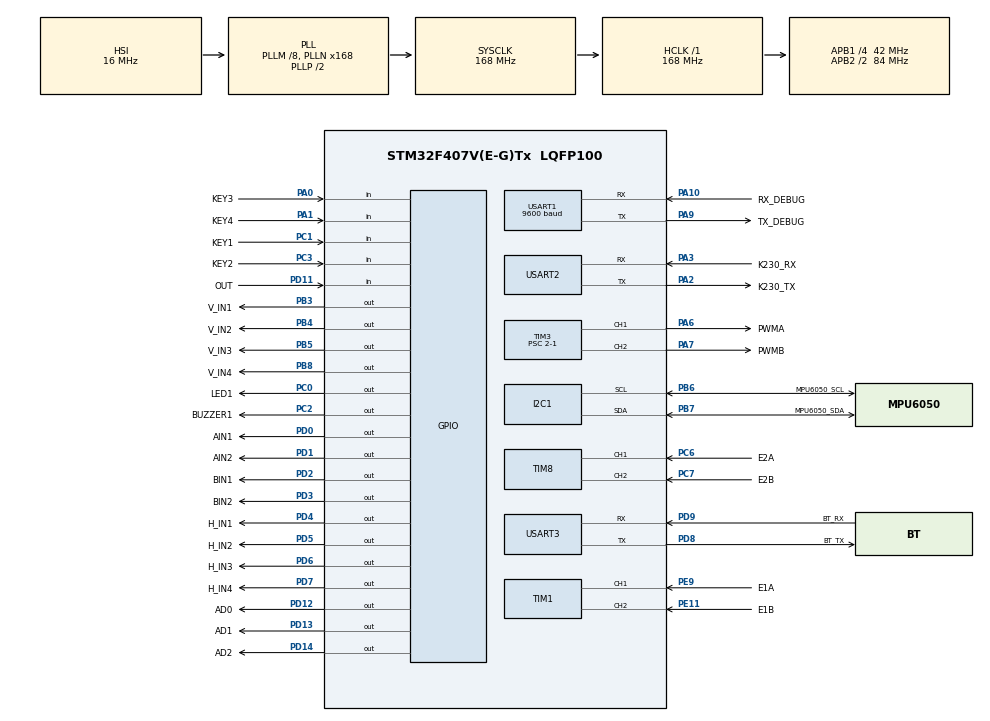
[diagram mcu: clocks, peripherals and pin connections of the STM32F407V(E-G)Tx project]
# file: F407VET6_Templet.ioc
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Dma.I2C1_RX.6.Direction=DMA_PERIPH_TO_MEMORY
Dma.I2C1_RX.6.FIFOMode=DMA_FIFOMODE_DISABLE
Dma.I2C1_RX.6.Instance=DMA1_Stream0
Dma.I2C1_RX.6.MemDataAlignment=DMA_MDATAALIGN_BYTE
Dma.I2C1_RX.6.MemInc=DMA_MINC_ENABLE
Dma.I2C1_RX.6.Mode=DMA_NORMAL
Dma.I2C1_RX.6.PeriphDataAlignment=DMA_PDATAALIGN_BYTE
Dma.I2C1_RX.6.PeriphInc=DMA_PINC_DISABLE
Dma.I2C1_RX.6.Priority=DMA_PRIORITY_LOW
Dma.I2C1_TX.7.Direction=DMA_MEMORY_TO_PERIPH
Dma.I2C1_TX.7.FIFOMode=DMA_FIFOMODE_DISABLE
Dma.I2C1_TX.7.Instance=DMA1_Stream7
Dma.I2C1_TX.7.MemDataAlignment=DMA_MDATAALIGN_BYTE
Dma.I2C1_TX.7.MemInc=DMA_MINC_ENABLE
Dma.I2C1_TX.7.Mode=DMA_NORMAL
Dma.I2C1_TX.7.PeriphDataAlignment=DMA_PDATAALIGN_BYTE
Dma.I2C1_TX.7.PeriphInc=DMA_PINC_DISABLE
Dma.I2C1_TX.7.Priority=DMA_PRIORITY_LOW
Dma.Request0=USART1_RX
Dma.Request1=USART1_TX
Dma.Request2=USART2_RX
Dma.Request3=USART2_TX
Dma.Request4=USART3_RX
Dma.Request5=USART3_TX
Dma.Request6=I2C1_RX
Dma.Request7=I2C1_TX
Dma.USART1_RX.0.Direction=DMA_PERIPH_TO_MEMORY
Dma.USART1_RX.0.FIFOMode=DMA_FIFOMODE_DISABLE
Dma.USART1_RX.0.Instance=DMA2_Stream2
Dma.USART1_RX.0.MemDataAlignment=DMA_MDATAALIGN_BYTE
Dma.USART1_RX.0.MemInc=DMA_MINC_ENABLE
Dma.USART1_RX.0.Mode=DMA_NORMAL
Dma.USART1_RX.0.PeriphDataAlignment=DMA_PDATAALIGN_BYTE
Dma.USART1_RX.0.PeriphInc=DMA_PINC_DISABLE
Dma.USART1_RX.0.Priority=DMA_PRIORITY_LOW
Dma.USART1_TX.1.Direction=DMA_MEMORY_TO_PERIPH
Dma.USART1_TX.1.FIFOMode=DMA_FIFOMODE_DISABLE
Dma.USART1_TX.1.Instance=DMA2_Stream7
Dma.USART1_TX.1.MemDataAlignment=DMA_MDATAALIGN_BYTE
Dma.USART1_TX.1.MemInc=DMA_MINC_ENABLE
Dma.USART1_TX.1.Mode=DMA_NORMAL
Dma.USART1_TX.1.PeriphDataAlignment=DMA_PDATAALIGN_BYTE
Dma.USART1_TX.1.PeriphInc=DMA_PINC_DISABLE
Dma.USART1_TX.1.Priority=DMA_PRIORITY_LOW
Dma.USART2_RX.2.Direction=DMA_PERIPH_TO_MEMORY
Dma.USART2_RX.2.FIFOMode=DMA_FIFOMODE_DISABLE
Dma.USART2_RX.2.Instance=DMA1_Stream5
Dma.USART2_RX.2.MemDataAlignment=DMA_MDATAALIGN_BYTE
Dma.USART2_RX.2.MemInc=DMA_MINC_ENABLE
Dma.USART2_RX.2.Mode=DMA_NORMAL
Dma.USART2_RX.2.PeriphDataAlignment=DMA_PDATAALIGN_BYTE
Dma.USART2_RX.2.PeriphInc=DMA_PINC_DISABLE
Dma.USART2_RX.2.Priority=DMA_PRIORITY_LOW
Dma.USART2_TX.3.Direction=DMA_MEMORY_TO_PERIPH
Dma.USART2_TX.3.FIFOMode=DMA_FIFOMODE_DISABLE
Dma.USART2_TX.3.Instance=DMA1_Stream6
Dma.USART2_TX.3.MemDataAlignment=DMA_MDATAALIGN_BYTE
Dma.USART2_TX.3.MemInc=DMA_MINC_ENABLE
Dma.USART2_TX.3.Mode=DMA_NORMAL
Dma.USART2_TX.3.PeriphDataAlignment=DMA_PDATAALIGN_BYTE
Dma.USART2_TX.3.PeriphInc=DMA_PINC_DISABLE
Dma.USART2_TX.3.Priority=DMA_PRIORITY_LOW
Dma.USART3_RX.4.Direction=DMA_PERIPH_TO_MEMORY
Dma.USART3_RX.4.FIFOMode=DMA_FIFOMODE_DISABLE
Dma.USART3_RX.4.Instance=DMA1_Stream1
Dma.USART3_RX.4.MemDataAlignment=DMA_MDATAALIGN_BYTE
Dma.USART3_RX.4.MemInc=DMA_MINC_ENABLE
Dma.USART3_RX.4.Mode=DMA_NORMAL
Dma.USART3_RX.4.PeriphDataAlignment=DMA_PDATAALIGN_BYTE
Dma.USART3_RX.4.PeriphInc=DMA_PINC_DISABLE
Dma.USART3_RX.4.Priority=DMA_PRIORITY_LOW
Dma.USART3_TX.5.Direction=DMA_MEMORY_TO_PERIPH
Dma.USART3_TX.5.FIFOMode=DMA_FIFOMODE_DISABLE
Dma.USART3_TX.5.Instance=DMA1_Stream3
Dma.USART3_TX.5.MemDataAlignment=DMA_MDATAALIGN_BYTE
Dma.USART3_TX.5.MemInc=DMA_MINC_ENABLE
Dma.USART3_TX.5.Mode=DMA_NORMAL
Dma.USART3_TX.5.PeriphDataAlignment=DMA_PDATAALIGN_BYTE
Dma.USART3_TX.5.PeriphInc=DMA_PINC_DISABLE
Dma.USART3_TX.5.Priority=DMA_PRIORITY_LOW
Mcu.Family=STM32F4
Mcu.Name=STM32F407V(E-G)Tx
Mcu.Package=LQFP100
NVIC.DMA1_Stream0_IRQn=true\:0\:0\:false\:false\:true\:false\:true\:true
NVIC.DMA1_Stream1_IRQn=true\:0\:0\:false\:false\:true\:false\:true\:true
NVIC.DMA1_Stream3_IRQn=true\:0\:0\:false\:false\:true\:false\:true\:true
NVIC.DMA1_Stream5_IRQn=true\:0\:0\:false\:false\:true\:false\:true\:true
NVIC.DMA1_Stream6_IRQn=true\:0\:0\:false\:false\:true\:false\:true\:true
NVIC.DMA1_Stream7_IRQn=true\:0\:0\:false\:false\:true\:false\:true\:true
NVIC.DMA2_Stream2_IRQn=true\:0\:0\:false\:false\:true\:false\:true\:true
NVIC.DMA2_Stream7_IRQn=true\:0\:0\:false\:false\:true\:false\:true\:true
NVIC.PriorityGroup=NVIC_PRIORITYGROUP_4
NVIC.TIM2_IRQn=true\:0\:0\:false\:false\:true\:true\:true\:true
NVIC.USART1_IRQn=true\:0\:0\:false\:false\:true\:true\:true\:true
NVIC.USART2_IRQn=true\:0\:0\:false\:false\:true\:true\:true\:true
NVIC.USART3_IRQn=true\:0\:0\:false\:false\:true\:true\:true\:true
PA0-WKUP.GPIO_Label=KEY3
PA0-WKUP.GPIO_PuPd=GPIO_PULLUP
PA0-WKUP.Signal=GPIO_Input
PA1.GPIO_Label=KEY4
PA1.GPIO_PuPd=GPIO_PULLUP
PA1.Signal=GPIO_Input
PA10.GPIO_Label=RX_DEBUG
PA10.Mode=Asynchronous
PA10.Signal=USART1_RX
PA13.Mode=Serial_Wire
PA13.Signal=SYS_JTMS-SWDIO
PA14.Mode=Serial_Wire
PA14.Signal=SYS_JTCK-SWCLK
PA2.GPIO_Label=K230_TX
PA2.Mode=Asynchronous
PA2.Signal=USART2_TX
PA3.GPIO_Label=K230_RX
PA3.Mode=Asynchronous
PA3.Signal=USART2_RX
PA6.GPIO_Label=PWMA
PA6.Signal=S_TIM3_CH1
PA7.GPIO_Label=PWMB
PA7.Signal=S_TIM3_CH2
PA9.GPIO_Label=TX_DEBUG
PA9.Mode=Asynchronous
PA9.Signal=USART1_TX
PB3.GPIO_Label=V_IN1
PB3.Signal=GPIO_Output
PB4.GPIO_Label=V_IN2
PB4.Signal=GPIO_Output
PB5.GPIO_Label=V_IN3
PB5.Signal=GPIO_Output
PB6.GPIO_Label=MPU6050_SCL
PB6.Mode=I2C
PB6.Signal=I2C1_SCL
PB7.GPIO_Label=MPU6050_SDA
PB7.Mode=I2C
PB7.Signal=I2C1_SDA
PB8.GPIO_Label=V_IN4
PB8.Signal=GPIO_Output
PC0.GPIO_Label=LED1
PC0.GPIO_Speed=GPIO_SPEED_FREQ_MEDIUM
PC0.Signal=GPIO_Output
PC1.GPIO_Label=KEY1
PC1.GPIO_PuPd=GPIO_PULLUP
PC1.Signal=GPIO_Input
PC2.GPIO_Label=BUZZER1
PC2.GPIO_Speed=GPIO_SPEED_FREQ_MEDIUM
PC2.Signal=GPIO_Output
PC3.GPIO_Label=KEY2
PC3.GPIO_PuPd=GPIO_PULLUP
PC3.Signal=GPIO_Input
PC6.GPIO_Label=E2A
PC6.Signal=S_TIM8_CH1
PC7.GPIO_Label=E2B
PC7.Signal=S_TIM8_CH2
PD0.GPIO_Label=AIN1
PD0.Signal=GPIO_Output
PD1.GPIO_Label=AIN2
PD1.Signal=GPIO_Output
PD11.GPIO_Label=OUT
PD11.Signal=GPIO_Input
PD12.GPIO_Label=AD0
PD12.Signal=GPIO_Output
PD13.GPIO_Label=AD1
PD13.Signal=GPIO_Output
PD14.GPIO_Label=AD2
PD14.Signal=GPIO_Output
PD2.GPIO_Label=BIN1
PD2.Signal=GPIO_Output
PD3.GPIO_Label=BIN2
PD3.Signal=GPIO_Output
PD4.GPIO_Label=H_IN1
PD4.Signal=GPIO_Output
PD5.GPIO_Label=H_IN2
PD5.Signal=GPIO_Output
PD6.GPIO_Label=H_IN3
PD6.Signal=GPIO_Output
PD7.GPIO_Label=H_IN4
PD7.Signal=GPIO_Output
PD8.GPIO_Label=BT_TX
PD8.Mode=Asynchronous
PD8.Signal=USART3_TX
PD9.GPIO_Label=BT_RX
PD9.Mode=Asynchronous
PD9.Signal=USART3_RX
PE11.GPIO_Label=E1B
PE11.Signal=S_TIM1_CH2
PE9.GPIO_Label=E1A
PE9.Signal=S_TIM1_CH1
PH0-OSC_IN.Mode=HSE-External-Oscillator
PH0-OSC_IN.Signal=RCC_OSC_IN
PH1-OSC_OUT.Mode=HSE-External-Oscillator
PH1-OSC_OUT.Signal=RCC_OSC_OUT
ProjectManager.HeapSize=0x200
ProjectManager.StackSize=0x2000
ProjectManager.TargetToolchain=CMake
RCC.48MHZClocksFreq_Value=84000000
RCC.AHBFreq_Value=168000000
RCC.APB1CLKDivider=RCC_HCLK_DIV4
RCC.APB1Freq_Value=42000000
RCC.APB1TimFreq_Value=84000000
RCC.APB2CLKDivider=RCC_HCLK_DIV2
RCC.APB2Freq_Value=84000000
RCC.APB2TimFreq_Value=168000000
RCC.CortexFreq_Value=168000000
RCC.HCLKFreq_Value=168000000
RCC.HSE_VALUE=25000000
RCC.HSI_VALUE=16000000
RCC.LSE_VALUE=32768
RCC.PLLM=8
RCC.PLLN=168
RCC.SYSCLKFreq_VALUE=168000000
RCC.SYSCLKSource=RCC_SYSCLKSOURCE_PLLCLK
RCC.VCOOutputFreq_Value=336000000
SH.S_TIM1_CH1.0=TIM1_CH1,Encoder_Interface
SH.S_TIM1_CH2.0=TIM1_CH2,Encoder_Interface
SH.S_TIM3_CH1.0=TIM3_CH1,PWM Generation1 CH1
SH.S_TIM3_CH2.0=TIM3_CH2,PWM Generation2 CH2
SH.S_TIM8_CH1.0=TIM8_CH1,Encoder_Interface
SH.S_TIM8_CH2.0=TIM8_CH2,Encoder_Interface
TIM1.EncoderMode=TIM_ENCODERMODE_TI12
TIM2.Period=1000-1
TIM2.Prescaler=84-1
TIM3.Channel-PWM\ Generation1\ CH1=TIM_CHANNEL_1
TIM3.Channel-PWM\ Generation2\ CH2=TIM_CHANNEL_2
TIM3.Period=2100-1
TIM3.Prescaler=2-1
TIM8.EncoderMode=TIM_ENCODERMODE_TI12
USART1.BaudRate=9600
USART1.VirtualMode=VM_ASYNC
USART2.VirtualMode=VM_ASYNC
USART3.VirtualMode=VM_ASYNC
VP_TIM2_VS_ClockSourceINT.Mode=Internal
VP_TIM3_VS_ClockSourceINT.Mode=Internal
board=custom

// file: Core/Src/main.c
/* USER CODE BEGIN Header */
/* USER CODE END Header */
#include "main.h"
#include "dma.h"
#include "i2c.h"
#include "tim.h"
#include "usart.h"
#include "gpio.h"

/* USER CODE BEGIN Includes */
// Test includes disabled — re-enable per-module when testing individually:
// #include "LedTest.h"
// #include "KeyTest.h"
// #include "StepperMotorTest.h"
// #include "DCMotorTest.h"
// #include "DebugPrintfTest.h"
// #include "EncoderTest.h"
// #include "MoveControlTest.h"
#include "Callback.h"
#include "Init.h"
#include "TaskSelector.h"
// #include "Vofa.h"  /* Task3 循迹期间禁用 Vofa，避免串口冲突 */
/* USER CODE END Includes */

/* USER CODE BEGIN PD */
/* TaskSelector — 按键选择: KEY1-4 → Task1-4 */
/* USER CODE END PD */

void SystemClock_Config(void);

int main(void)
{

  /* MCU Configuration--------------------------------------------------------*/

  /* Reset of all peripherals, Initializes the Flash interface and the Systick. */
  HAL_Init();

  /* Configure the system clock */
  SystemClock_Config();

  /* Initialize all configured peripherals */
  MX_GPIO_Init();
  MX_DMA_Init();
  MX_USART1_UART_Init();
  MX_TIM1_Init();
  MX_TIM2_Init();
  MX_TIM3_Init();
  MX_TIM8_Init();
  MX_USART2_UART_Init();
  MX_USART3_UART_Init();
  MX_I2C1_Init();
  /* USER CODE BEGIN 2 */
  Callback_Init();           /* 启动 TIM2 1ms 基时 + 软件分频 */
  Framework_Init();          /* 初始化所有硬件模块 + 运动控制 */
  TaskSelector_Init();       /* 按键选择任务: KEY1-4 → Task1-4 */
  // Vofa_Init(&dbg_printf.uart, &move_ctrl);  /* Task3 期间禁用 */
  /* USER CODE END 2 */

  /* Infinite loop */
  /* USER CODE BEGIN WHILE */
  while(1){
    /* 40ms 周期调度: 编码器更新 + 运动控制 (巡线模式下 MoveControl_Update 静默返回) */
    if (Flag_40ms) {
      Flag_40ms = 0;
      Framework_IRQHandler();

      /* Vofa 遥测 — Task3 期间禁用，避免占用 UART1 带宽 */
      // static uint32_t last_vofa = 0;
      // uint32_t now = HAL_GetTick();
      // if (now - last_vofa >= 100) {
      //   last_vofa = now;
      //   Vofa_SendTelemetry();
      // }
    }

    /* 按键选择 + 任务分发: IDLE等待按键 → RUNNING执行任务 → 完成后回IDLE */
    TaskSelector_Loop();

    /* 陀螺仪调试打印 — Task1 期间禁用，状态由 Task1_LineTrack_Loop 统一输出 */
    // static uint32_t last_gyro = 0;
    // uint32_t now = HAL_GetTick();
    // if (now - last_gyro >= 200) {
    //   last_gyro = now;
    //   Gyro_PrintInfo(&gyro, &dbg_printf);
    // }
  }
    /* USER CODE END WHILE */

}

void SystemClock_Config(void)
{
  RCC_OscInitTypeDef RCC_OscInitStruct = {0};
  RCC_ClkInitTypeDef RCC_ClkInitStruct = {0};

  /** Configure the main internal regulator output voltage
  */
  __HAL_RCC_PWR_CLK_ENABLE();
  __HAL_PWR_VOLTAGESCALING_CONFIG(PWR_REGULATOR_VOLTAGE_SCALE1);

  /** Initializes the RCC Oscillators according to the specified parameters
  * in the RCC_OscInitTypeDef structure.
  */
  RCC_OscInitStruct.OscillatorType = RCC_OSCILLATORTYPE_HSI;
  RCC_OscInitStruct.HSIState = RCC_HSI_ON;
  RCC_OscInitStruct.HSICalibrationValue = RCC_HSICALIBRATION_DEFAULT;
  RCC_OscInitStruct.PLL.PLLState = RCC_PLL_ON;
  RCC_OscInitStruct.PLL.PLLSource = RCC_PLLSOURCE_HSI;
  RCC_OscInitStruct.PLL.PLLM = 8;
  RCC_OscInitStruct.PLL.PLLN = 168;
  RCC_OscInitStruct.PLL.PLLP = RCC_PLLP_DIV2;
  RCC_OscInitStruct.PLL.PLLQ = 4;
  if (HAL_RCC_OscConfig(&RCC_OscInitStruct) != HAL_OK)
  {
    Error_Handler();
  }

  /** Initializes the CPU, AHB and APB buses clocks
  */
  RCC_ClkInitStruct.ClockType = RCC_CLOCKTYPE_HCLK|RCC_CLOCKTYPE_SYSCLK
                              |RCC_CLOCKTYPE_PCLK1|RCC_CLOCKTYPE_PCLK2;
  RCC_ClkInitStruct.SYSCLKSource = RCC_SYSCLKSOURCE_PLLCLK;
  RCC_ClkInitStruct.AHBCLKDivider = RCC_SYSCLK_DIV1;
  RCC_ClkInitStruct.APB1CLKDivider = RCC_HCLK_DIV4;
  RCC_ClkInitStruct.APB2CLKDivider = RCC_HCLK_DIV2;

  if (HAL_RCC_ClockConfig(&RCC_ClkInitStruct, FLASH_LATENCY_5) != HAL_OK)
  {
    Error_Handler();
  }
}

void Error_Handler(void)
{
}
